# S6E1B8xE register map
Vendor: Cypress; File version: 2.1
CPU: CM0PLUS r0p1, little endian, no MPU, no FPU, 2 interrupt priority bits
Registers are 8-bit, read-write, reset 0x0 unless marked. A register's access mark holds for its fields unless they carry their own. Offsets are from the block's base; [hi:lo] are bit positions; 'fields as' and 'values as' point back to an identical list.

## UNIQUE_ID
Base 0x40000200
0x00 UIDR0 32-bit ro reset not defined — Unique ID Register 0 [W]
  [31:4] UID — Unique ID 27 through Unique ID 0
0x04 UIDR1 32-bit ro reset not defined — Unique ID Register 1 [W]
  [12:0] UID — Unique ID 40 through Unique ID 28

## HWWDT — Hardware Watchdog Timer
Base 0x40011000
0x00 WDG_LDR 32-bit reset 0xFFFF — Hardware Watchdog Timer Load Register [W]
0x04 WDG_VLR 32-bit ro reset 0xFFFF — Hardware Watchdog Timer Value Register [W]
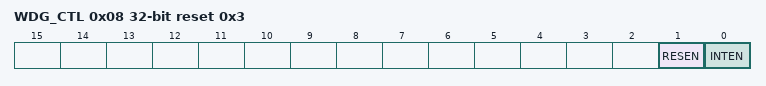
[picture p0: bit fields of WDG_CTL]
0x08 WDG_CTL 32-bit reset 0x3 — Hardware Watchdog Timer Control Register [W]
  [1] RESEN — Hardware watchdog reset enable bit
  [0] INTEN — Hardware watchdog interrupt and counter enable bit
0x0C WDG_ICL 32-bit reset not defined — Hardware Watchdog Timer Clear Register [W]
0x10 WDG_RIS 32-bit ro — Hardware Watchdog Timer Interrupt Status Register [W]
  [0] RIS — Hardware watchdog interrupt status bit
0xC00 WDG_LCK 32-bit reset 0x1 — Hardware Watchdog Timer Lock Register [W]

## SWWDT — Software Watchdog Timer
Base 0x40012000
0x00 WDOGLOAD 32-bit reset 0xFFFFFFFF — Software Watchdog Timer Load Register [W]
0x04 WDOGVALUE 32-bit ro reset 0xFFFFFFFF — Software Watchdog Timer Value Register [W]
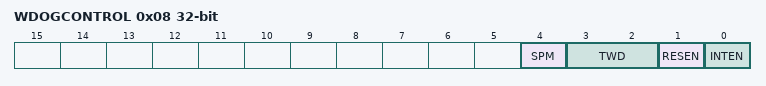
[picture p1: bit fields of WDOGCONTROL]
0x08 WDOGCONTROL 32-bit — Software Watchdog Timer Control Register [W]
  [4] SPM — Software Watchdog window watchdog mode enable bit
  [3:2] TWD — Timing window setting bit of the software watchdog
  [1] RESEN — Reset enable bit of the software watchdog
  [0] INTEN — Interrupt and counter enable bit of the software watchdog
0x0C WDOGINTCLR 32-bit reset not defined — Software Watchdog Timer Clear Register [W]
0x10 WDOGRIS 32-bit ro — Software Watchdog Timer Interrupt Status Register [W]
  [0] RIS — Software watchdog interrupt status bit
0x18 WDOGSPMC 32-bit — Software Watchdog Timer Window Watchdog Mode Control Register [W]
  [0] TGR — Software watchdog trigger type bit
0xC00 WDOGLOCK 32-bit — Software Watchdog Timer Lock Register [W]

## DT — Dual Timer
Base 0x40015000
0x00 TIMER1LOAD 32-bit — Load Register [W]
0x04 TIMER1VALUE 32-bit ro reset 0xFFFFFFFF — Value Register [W]
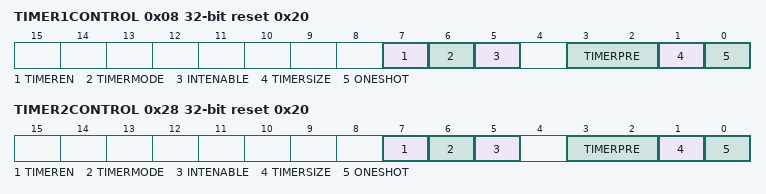
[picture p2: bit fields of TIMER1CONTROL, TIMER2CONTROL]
0x08 TIMER1CONTROL 32-bit reset 0x20 — Control Register [W]
  [7] TIMEREN — Enable bit
  [6] TIMERMODE — Mode bit
  [5] INTENABLE — Interrupt enable bit
  [3:2] TIMERPRE — Prescale bits
  [1] TIMERSIZE — Counter size bit
  [0] ONESHOT — One-shot mode bit
0x0C TIMER1INTCLR 32-bit wo reset not defined — Interrupt Clear Register [W]
0x10 TIMER1RIS 32-bit ro — Interrupt Status Register [W]
  [0] TIMER1RIS — Interrupt Status Register bit
0x14 TIMER1MIS 32-bit ro — Masked Interrupt Status Register [W]
  [0] TIMER1MIS — Masked Interrupt Status bit
0x18 TIMER1BGLOAD 32-bit — Background Load Register [W]
0x20 TIMER2LOAD 32-bit — Load Register [W]
0x24 TIMER2VALUE 32-bit ro reset 0xFFFFFFFF — Value Register [W]
0x28 TIMER2CONTROL 32-bit reset 0x20 — Control Register [W]
  fields as TIMER1CONTROL
0x2C TIMER2INTCLR 32-bit wo reset not defined — Interrupt Clear Register [W]
0x30 TIMER2RIS 32-bit ro — Interrupt Status Register [W]
  [0] TIMER2RIS — Interrupt Status Register bit
0x34 TIMER2MIS 32-bit ro — Masked Interrupt Status Register [W]
  [0] TIMER2MIS — Masked Interrupt Status bit
0x38 TIMER2BGLOAD 32-bit — Background Load Register [W]

## BT0 — Base Timer 0
Base 0x40025000
Same registers: BT1 0x40025040, BT2 0x40025080, BT3 0x400250C0, BT4 0x40025200, BT5 0x40025240, BT6 0x40025280, BT7 0x400252C0
0x00 PWM_PCSR 16-bit (PWM view) — PWM Cycle Set Register [HW]
0x00 PPG_PRLL 16-bit (PPG view) — LOW Width Reload Register [HW]
0x00 RT_PCSR 16-bit (RT view) — Cycle Set Register [HW]
0x04 PWM_PDUT 16-bit (PWM view) — PWM Duty Set Register [HW]
0x04 PPG_PRLH 16-bit (PPG view) — HIGH Width Reload Register [HW]
0x04 PWC_DTBF 16-bit ro (PWC view) — Data Buffer Register [HW]
0x08 PWM_TMR 16-bit ro (PWM view) — Timer Register [HW]
0x08 PPG_TMR 16-bit ro (PPG view) — Timer Register [HW]
0x08 RT_TMR 16-bit ro (RT view) — Timer Register [HW]
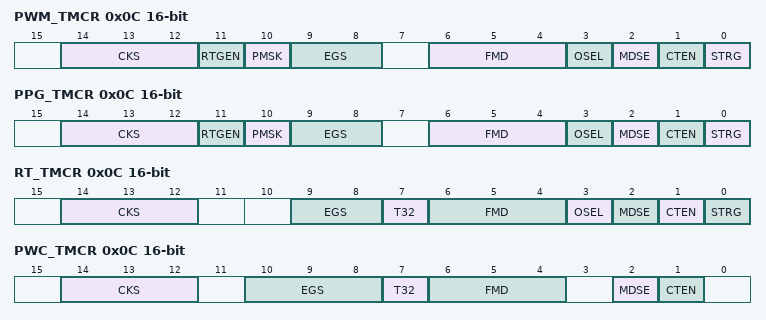
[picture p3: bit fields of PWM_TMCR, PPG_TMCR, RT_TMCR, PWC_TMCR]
0x0C PWM_TMCR 16-bit (PWM view) — Timer Control Register [BHW]
  [14:12] CKS — Count clock selection bits
  [11] RTGEN — Restart enable bit
  [10] PMSK — Pulse output mask bit
  [9:8] EGS — Trigger input edge selection bits
  [6:4] FMD — Timer function selection bits
  [3] OSEL — Output polarity specification bit
  [2] MDSE — Mode selection bit
  [1] CTEN — Count operation enable bit
  [0] STRG — Software trigger bit
0x0C PPG_TMCR 16-bit (PPG view) — Timer Control Register [BHW]
  fields as PWM_TMCR
0x0C RT_TMCR 16-bit (RT view) — Timer Control Register [BHW]
  [14:12] CKS — Count clock selection bits
  [9:8] EGS — Slection bits of trigger input edge and gate function level
  [7] T32 — 32-bit timer selection bit
  [6:4] FMD — Timer function selection bits
  [3] OSEL — Output polarity specification bit
  [2] MDSE — Mode selection bit
  [1] CTEN — Timer enable bit
  [0] STRG — Software trigger bit
0x0C PWC_TMCR 16-bit (PWC view) — Timer Control Register [BHW]
  [14:12] CKS — Count clock selection bits
  [10:8] EGS — Measurement edge selection bits
  [7] T32 — 32-bit timer selection bit
  [6:4] FMD — Timer function selection bits
  [2] MDSE — Mode selection bit
  [1] CTEN — Timer enable bit
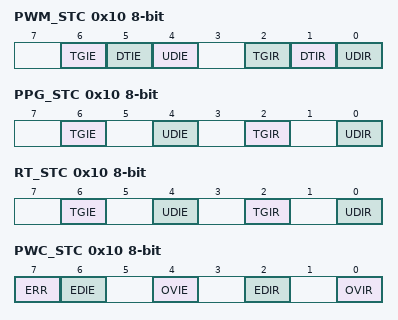
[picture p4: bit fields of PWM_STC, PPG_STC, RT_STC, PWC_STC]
0x10 PWM_STC (PWM view) — Status Control Register [BHW]
  [6] TGIE — Trigger interrupt request enable bit
  [5] DTIE — Duty match interrupt request enable bit
  [4] UDIE — Underflow interrupt request enable bit
  [2] TGIR — Trigger interrupt request bit
  [1] DTIR — Duty match interrupt request bit
  [0] UDIR — Underflow interrupt request bit
0x10 PPG_STC (PPG view) — Status Control Register [BHW]
  [6] TGIE — Trigger interrupt request enable bit
  [4] UDIE — Underflow interrupt request enable bit
  [2] TGIR — Trigger interrupt request bit
  [0] UDIR — Underflow interrupt request bit
0x10 RT_STC (RT view) — Status Control Register [BHW]
  fields as PPG_STC
0x10 PWC_STC (PWC view) — Status Control Register [BHW]
  [7] ERR ro — Error flag bit
  [6] EDIE — Measurement completion interrupt request enable bit
  [4] OVIE — Overflow interrupt request enable bit
  [2] EDIR ro — Measurement completion interrupt request bit
  [0] OVIR — Overflow interrupt request bit
0x11 PWM_TMCR2 (PWM view) — Timer Control Register 2 [BHW]
  [0] CKS3 — Count clock selection bit
0x11 PPG_TMCR2 (PPG view) — Timer Control Register 2 [BHW]
  [0] CKS3 — Count clock selection bit
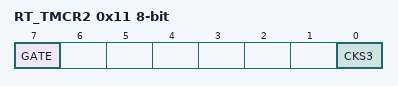
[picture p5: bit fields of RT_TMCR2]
0x11 RT_TMCR2 (RT view) — Timer Control Register 2 [BHW]
  [7] GATE — Gate Input Enable bit
  [0] CKS3 — Count clock selection bit
0x11 PWC_TMCR2 (PWC view) — Timer Control Register 2 [BHW]
  [0] CKS3 — Count clock selection bit
